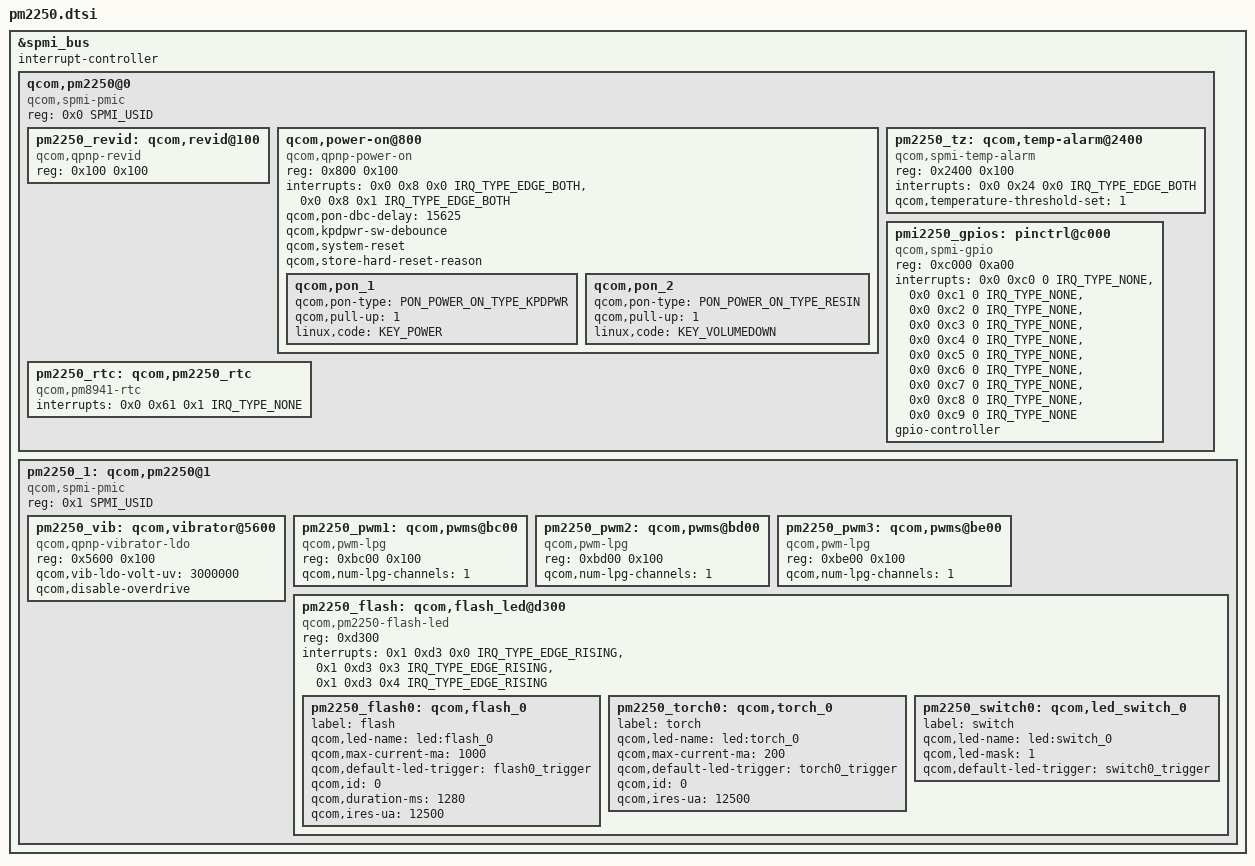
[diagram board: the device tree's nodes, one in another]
#include <dt-bindings/input/input.h>
#include <dt-bindings/input/qcom,qpnp-power-on.h>
#include <dt-bindings/interrupt-controller/irq.h>
#include <dt-bindings/spmi/spmi.h>

&spmi_bus {
	#address-cells = <2>;
	#size-cells = <0>;
	interrupt-controller;
	#interrupt-cells = <4>;

	qcom,pm2250@0 {
		compatible = "qcom,spmi-pmic";
		reg = <0x0 SPMI_USID>;
		#address-cells = <2>;
		#size-cells = <0>;

		pm2250_revid: qcom,revid@100 {
			compatible = "qcom,qpnp-revid";
			reg = <0x100 0x100>;
		};

		qcom,power-on@800 {
			compatible = "qcom,qpnp-power-on";
			reg = <0x800 0x100>;
			interrupts = <0x0 0x8 0x0 IRQ_TYPE_EDGE_BOTH>,
					<0x0 0x8 0x1 IRQ_TYPE_EDGE_BOTH>;
			interrupt-names = "kpdpwr", "resin";
			qcom,pon-dbc-delay = <15625>;
			qcom,kpdpwr-sw-debounce;
			qcom,system-reset;
			qcom,store-hard-reset-reason;

			qcom,pon_1 {
				qcom,pon-type = <PON_POWER_ON_TYPE_KPDPWR>;
				qcom,pull-up = <1>;
				linux,code = <KEY_POWER>;
			};

			qcom,pon_2 {
				qcom,pon-type = <PON_POWER_ON_TYPE_RESIN>;
				qcom,pull-up = <1>;
				linux,code = <KEY_VOLUMEDOWN>;
			};
		};

		pm2250_tz: qcom,temp-alarm@2400 {
			compatible = "qcom,spmi-temp-alarm";
			reg = <0x2400 0x100>;
			interrupts = <0x0 0x24 0x0 IRQ_TYPE_EDGE_BOTH>;
			#thermal-sensor-cells = <0>;
			qcom,temperature-threshold-set = <1>;
		};

		pmi2250_gpios: pinctrl@c000 {
			compatible = "qcom,spmi-gpio";
			reg = <0xc000 0xa00>;
			interrupts = <0x0 0xc0 0 IRQ_TYPE_NONE>,
					<0x0 0xc1 0 IRQ_TYPE_NONE>,
					<0x0 0xc2 0 IRQ_TYPE_NONE>,
					<0x0 0xc3 0 IRQ_TYPE_NONE>,
					<0x0 0xc4 0 IRQ_TYPE_NONE>,
					<0x0 0xc5 0 IRQ_TYPE_NONE>,
					<0x0 0xc6 0 IRQ_TYPE_NONE>,
					<0x0 0xc7 0 IRQ_TYPE_NONE>,
					<0x0 0xc8 0 IRQ_TYPE_NONE>,
					<0x0 0xc9 0 IRQ_TYPE_NONE>;

			interrupt-names = "pm2250_gpio1", "pm2250_gpio2",
					"pm2250_gpio3", "pm2250_gpio4",
					"pm2250_gpio5", "pm2250_gpio6",
					"pm2250_gpio7", "pm2250_gpio8",
					"pm2250_gpio9", "pm2250_gpio10";

			gpio-controller;
			#gpio-cells = <2>;
		};

		pm2250_rtc: qcom,pm2250_rtc {
			compatible = "qcom,pm8941-rtc";
			interrupts = <0x0 0x61 0x1 IRQ_TYPE_NONE>;
		};
	};

	pm2250_1: qcom,pm2250@1 {
		compatible = "qcom,spmi-pmic";
		reg = <0x1 SPMI_USID>;
		#address-cells = <2>;
		#size-cells = <0>;

		pm2250_vib: qcom,vibrator@5600 {
			compatible = "qcom,qpnp-vibrator-ldo";
			reg = <0x5600 0x100>;
			qcom,vib-ldo-volt-uv = <3000000>;
			qcom,disable-overdrive;
		};

		pm2250_pwm1: qcom,pwms@bc00 {
			compatible = "qcom,pwm-lpg";
			reg = <0xbc00 0x100>;
			reg-names = "lpg-base";
			qcom,num-lpg-channels = <1>;
			#pwm-cells = <2>;
		};

		pm2250_pwm2: qcom,pwms@bd00 {
			compatible = "qcom,pwm-lpg";
			reg = <0xbd00 0x100>;
			reg-names = "lpg-base";
			qcom,num-lpg-channels = <1>;
			#pwm-cells = <2>;
		};

		pm2250_pwm3: qcom,pwms@be00 {
			compatible = "qcom,pwm-lpg";
			reg = <0xbe00 0x100>;
			reg-names = "lpg-base";
			qcom,num-lpg-channels = <1>;
			#pwm-cells = <2>;
		};

		pm2250_flash: qcom,flash_led@d300 {
			compatible = "qcom,pm2250-flash-led";
			reg = <0xd300>;
			interrupts = <0x1 0xd3 0x0 IRQ_TYPE_EDGE_RISING>,
				     <0x1 0xd3 0x3 IRQ_TYPE_EDGE_RISING>,
				     <0x1 0xd3 0x4 IRQ_TYPE_EDGE_RISING>;
			interrupt-names = "led-fault-irq",
					  "all-ramp-down-done-irq",
					  "all-ramp-up-done-irq";

			pm2250_flash0: qcom,flash_0 {
				label = "flash";
				qcom,led-name = "led:flash_0";
				qcom,max-current-ma = <1000>;
				qcom,default-led-trigger = "flash0_trigger";
				qcom,id = <0>;
				qcom,duration-ms = <1280>;
				qcom,ires-ua = <12500>;
			};

			pm2250_torch0: qcom,torch_0 {
				label = "torch";
				qcom,led-name = "led:torch_0";
				qcom,max-current-ma = <200>;
				qcom,default-led-trigger = "torch0_trigger";
				qcom,id = <0>;
				qcom,ires-ua = <12500>;
			};

			pm2250_switch0: qcom,led_switch_0 {
				label = "switch";
				qcom,led-name = "led:switch_0";
				qcom,led-mask = <1>;
				qcom,default-led-trigger = "switch0_trigger";
			};
		};
	};
};
